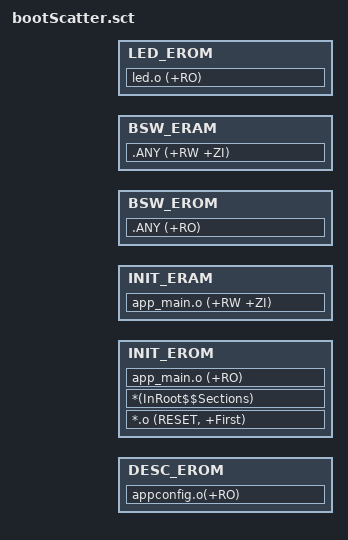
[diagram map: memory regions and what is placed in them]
#! armcc -E
#include "./scatterConfig.h"

; *************************************************************
; *** Scatter-Loading Description File generated by uVision ***
; *************************************************************

; *************************************************************
; *** Application DESC module *********************************
; *************************************************************
DESC_LROM       DESC_RO_BASE    DESC_RO_SIZE  {     ; load region SIZE_region
    DESC_EROM   DESC_RO_BASE    DESC_RO_SIZE  {     ; load address = execution address
        appconfig.o(+RO)
    }
}

; *************************************************************
; *** Application INIT module *********************************
; *************************************************************
INIT_ROM        INIT_RO_BASE    INIT_RO_SIZE  {     ; load region SIZE_region
    INIT_EROM   INIT_RO_BASE    INIT_RO_SIZE  {     ; load address = execution address
        *.o (RESET, +First)
        *(InRoot$$Sections)
        app_main.o (+RO)
    }
    INIT_ERAM   INIT_RW_BASE    INIT_RW_SIZE  {     ; load address = execution address
        app_main.o (+RW +ZI)
    }
}

; *************************************************************
; *** Application BSW module *********************************
; *************************************************************
BSW_LROM        BSW_RO_BASE     BSW_RO_SIZE  {      ; load region SIZE_region
    BSW_EROM    BSW_RO_BASE     BSW_RO_SIZE  {      ; load address = execution address
        .ANY (+RO)
    }
    BSW_ERAM    BSW_RW_BASE     BSW_RW_SIZE {
        .ANY (+RW +ZI)
    }
}

; *************************************************************
; *** Application LED module *********************************
; *************************************************************
LED_LROM        LED_RO_BASE     LED_RO_SIZE  {      ; load region SIZE_region
    LED_EROM    LED_RO_BASE     LED_RO_SIZE  {      ; load address = execution address
        led.o (+RO)
    }
}




